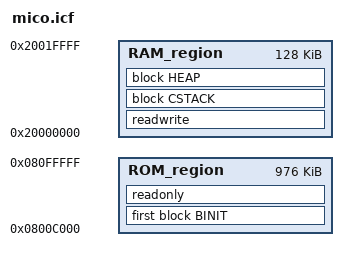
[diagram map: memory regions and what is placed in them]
/*
 * Copyright (C) Jinfeng Zhuang, 2015-4
 *
 * All Rights Reserved
 */

/*-Specials-*/
define symbol __ICFEDIT_intvec_start__ = 0x0800c000;
/*-Memory Regions-*/
define symbol __ICFEDIT_region_ROM_start__ = 0x0800c000;
define symbol __ICFEDIT_region_ROM_end__   = 0x080FFFFF;
define symbol __ICFEDIT_region_RAM_start__ = 0x20000000;
define symbol __ICFEDIT_region_RAM_end__   = 0x2001FFFF;

/*-Sizes-*/
define symbol __ICFEDIT_size_cstack__ = 0x200;
define symbol __ICFEDIT_size_heap__   = 0x12000;
/**** End of ICF editor section. ###ICF###*/

define memory mem with size = 4G;
define region ROM_region   = mem:[from __ICFEDIT_region_ROM_start__   to __ICFEDIT_region_ROM_end__];
define region RAM_region   = mem:[from __ICFEDIT_region_RAM_start__   to __ICFEDIT_region_RAM_end__];

define block CSTACK    with alignment = 8, size = __ICFEDIT_size_cstack__   { };
define block HEAP      with alignment = 8, size = __ICFEDIT_size_heap__     { };
define block BINIT with fixed order 
	{
		section .intvec, 
		section .sdt,
		section .machine_desc,
		section .initcall3.init,
		section .initcall6.init
	};

initialize by copy { readwrite };
do not initialize  { section .noinit };

place in ROM_region   {first block BINIT, readonly };
place in RAM_region   { readwrite, block CSTACK, block HEAP };
